# STM32C5A3 register map
File version: 0.1
CPU: CM33 r0p4, little endian, MPU, FPU, 4 interrupt priority bits
Registers are 32-bit, read-write, reset 0x0 unless marked. A register's access mark holds for its fields unless they carry their own. Offsets are from the block's base; [hi:lo] are bit positions; {n}, {i} and the like mark numbered series.

## COMP — COMP address block description
Base 0x40004000
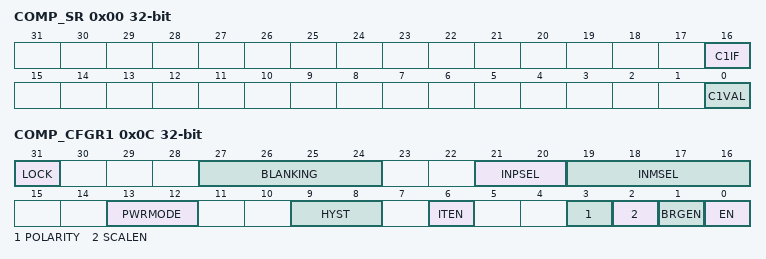
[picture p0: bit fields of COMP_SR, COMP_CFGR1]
0x00 COMP_SR ro — Comparator status register
  [16] C1IF — COMP1 Channel interrupt flag
  [0] C1VAL — COMP1 Channel output status bit
0x04 COMP_ICFR — Comparator interrupt clear flag register
  [16] CC1IF — Clear COMP Channel1 interrupt flag
0x0C COMP_CFGR1 — Comparator configuration register 1
  [31] LOCK
    0=COMP_CFGR1[31:0] register is read/write; 1=COMP_CFGR1[31:0] and COMP_OR registers are read-only
  [27:24] BLANKING — COMP Channel blanking source selection
    0=No blanking; {v}=comp_blk{v} (v=1..6)
  [21:20] INPSEL — COMP non-inverting input selection
  [19:16] INMSEL — COMP Channel inverting input selection
  [13:12] PWRMODE — Power mode of the COMP Channel
    0=High speed / full power; 1=Medium speed / medium power
  [9:8] HYST — COMP Channel hysteresis selection
    0=No hysteresis; 1=Low hysteresis; 2=Medium hysteresis; 3=High hysteresis
  [6] ITEN — COMP Channel interrupt enable
    0=Interrupt generation disabled for COMP Channel; 1=Interrupt generation enabled for COMP Channel
  [3] POLARITY — COMP Channel polarity selection
    0=COMP Channel output is not inverted; 1=COMP Channel output is inverted
  [2] SCALEN — Voltage scaler enable
    0=Vless thansub>REFINTless than/sub> scaler disabled; 1=Vless thansub>REFINTless than/sub> scaler enabled
  [1] BRGEN — Scaler bridge enable
    0=Scaler resistor bridge disabled; 1=Scaler resistor bridge enabled
  [0] EN — COMP Channel enable
    0=Disable; 1=Enable

## CORDIC — CORDIC register block
Base 0x40023800
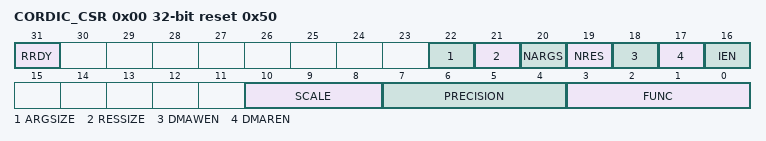
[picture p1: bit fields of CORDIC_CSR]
0x00 CORDIC_CSR reset 0x50 — CORDIC control/status register
  [31] RRDY ro — Result ready flag
    0=No new data in output register; 1=CORDIC_RDATA register contains new data
  [22] ARGSIZE — Width of input data
    0=32-bit; 1=16-bit
  [21] RESSIZE — Width of output data
    0=32-bit; 1=16-bit
  [20] NARGS — Number of arguments expected by the CORDIC_WDATA register
    0=Only one 32-bit write (or two 16-bit values if ARGSIZE = 1) is needed for the next calculation; 1=Two 32-bit values must be written to the CORDIC_WDATA register to trigger the next calculation
  [19] NRES — Number of results in the CORDIC_RDATA register
    0=Only one 32-bit value (or two 16-bit values if RESSIZE = 1) is transferred to the CORDIC_RDATA register on completion of the next calculation; 1=Two 32-bit values are transferred to the CORDIC_RDATA register on completion of the next calculation
  [18] DMAWEN — Enable DMA write channel
    0=Disabled; 1=Enabled
  [17] DMAREN — Enable DMA read channel
    0=Disabled; 1=Enabled
  [16] IEN — Enable interrupt.
    0=Disabled; 1=Enabled
  [10:8] SCALE — Scaling factor
  [7:4] PRECISION — Precision required (number of iterations)
  [3:0] FUNC — Function
    0=Cosine; 1=Sine
0x04 CORDIC_WDATA wo reset not defined — CORDIC argument register
  [31:0] ARG — Function input arguments
0x08 CORDIC_RDATA ro — CORDIC result register
  [31:0] RES — Function result

## CRC — CRC address block description
Base 0x40023000
0x00 CRC_DR reset 0xFFFFFFFF — CRC data register
  [31:0] DR — Data register bits
0x04 CRC_IDR — CRC independent data register
  [31:0] IDR — General-purpose 32-bit data register bits
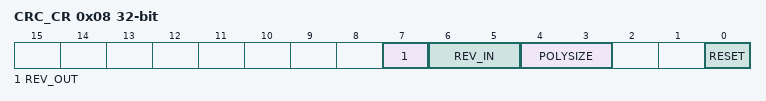
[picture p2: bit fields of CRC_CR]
0x08 CRC_CR — CRC control register
  [7] REV_OUT — Reverse output data
    0=Bit order not affected; 1=Bit-reversed output format
  [6:5] REV_IN — Reverse input data
    0=Bit order not affected; 1=Bit reversal done by byte; 2=Bit reversal done by half-word; 3=Bit reversal done by word
  [4:3] POLYSIZE — Polynomial size
    0=32 bit polynomial; 1=16 bit polynomial; 2=8 bit polynomial; 3=7 bit polynomial
  [0] RESET — RESET bit
0x10 CRC_INIT reset 0xFFFFFFFF — CRC initial value
  [31:0] CRC_INIT — Programmable initial CRC value
0x14 CRC_POL reset 0x4C11DB7 — CRC polynomial
  [31:0] POL — Programmable polynomial

## Notices in the file
Copyright (c) 2025 STMicroelectronics.
SPDX-License-Identifier: Apache-2.0
Licensed under the Apache License, Version 2.0 (the  License );
you may not use this file except in compliance with the License.
You may obtain a copy of the License at
http://www.apache.org/licenses/LICENSE-2.0
Unless required by applicable law or agreed to in writing, software
distributed under the License is distributed on an  AS IS  BASIS,
WITHOUT WARRANTIES OR CONDITIONS OF ANY KIND, either express or implied.
See the License for the specific language governing permissions and
limitations under the License.
